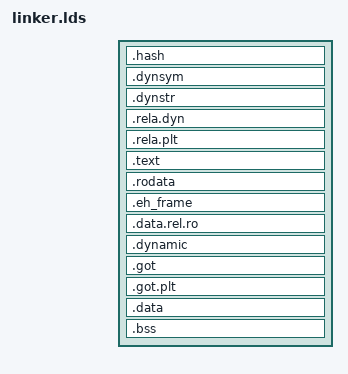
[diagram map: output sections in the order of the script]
/*******************************************************************************
* Copyright (c) 2015 Intel Corporation
*
* Licensed under the Apache License, Version 2.0 (the "License");
* you may not use this file except in compliance with the License.
* You may obtain a copy of the License at
*
*      http://www.apache.org/licenses/LICENSE-2.0
*
* Unless required by applicable law or agreed to in writing, software
* distributed under the License is distributed on an "AS IS" BASIS,
* WITHOUT WARRANTIES OR CONDITIONS OF ANY KIND, either express or implied.
* See the License for the specific language governing permissions and
* limitations under the License.
*******************************************************************************/

OUTPUT_FORMAT("elf64-x86-64", "elf64-x86-64",
	      "elf64-x86-64")
OUTPUT_ARCH(i386:x86-64)

ENTRY(mon_main_asm);

SECTIONS
{
  /* Read-only sections, merged into text segment: */
  . = SEGMENT_START("text-segment", 0) + SIZEOF_HEADERS;
  .hash           : { *(.hash) }
  .dynsym         : { *(.dynsym) }
  .dynstr         : { *(.dynstr) }
  .rela.dyn       :
    {
      *(.rela.init)
      *(.rela.text .rela.text.* .rela.gnu.linkonce.t.*)
      *(.rela.fini)
      *(.rela.rodata .rela.rodata.* .rela.gnu.linkonce.r.*)
      *(.rela.data .rela.data.* .rela.gnu.linkonce.d.*)
      *(.rela.tdata .rela.tdata.* .rela.gnu.linkonce.td.*)
      *(.rela.tbss .rela.tbss.* .rela.gnu.linkonce.tb.*)
      *(.rela.ctors)
      *(.rela.dtors)
      *(.rela.got)
      *(.rela.bss .rela.bss.* .rela.gnu.linkonce.b.*)
      *(.rela.ldata .rela.ldata.* .rela.gnu.linkonce.l.*)
      *(.rela.lbss .rela.lbss.* .rela.gnu.linkonce.lb.*)
      *(.rela.lrodata .rela.lrodata.* .rela.gnu.linkonce.lr.*)
      *(.rela.ifunc)
    }
  .rela.plt       :
    {
      *(.rela.plt)
      *(.rela.iplt)
    }
  .text           :
  {
    *(.text.unlikely .text.*_unlikely)
    *(.text.exit .text.exit.*)
    *(.text.startup .text.startup.*)
    *(.text.hot .text.hot.*)
    *(.text .stub .text.* .gnu.linkonce.t.*)
    /* .gnu.warning sections are handled specially by elf32.em.  */
    *(.gnu.warning)
  } =0x90909090
  .rodata         : { *(.rodata .rodata.* .gnu.linkonce.r.*) }
  .eh_frame       : { *(.eh_frame) }
  /* Adjust the address for the data segment.  We want to adjust up to
     the same address within the page on the next page up.  */
  . = ALIGN (4k);
  .data.rel.ro : { *(.data.rel.ro.local* .gnu.linkonce.d.rel.ro.local.*) *(.data.rel.ro* .gnu.linkonce.d.rel.ro.*) }
  .dynamic        : { *(.dynamic) }
  .got            : { *(.got) *(.igot) }
  .got.plt        : { *(.got.plt)  *(.igot.plt) }
  .data           :
  {
    *(.data .data.* .gnu.linkonce.d.*)
  }
  .bss            :
  {
   *(.dynbss)
   *(.bss .bss.* .gnu.linkonce.b.*)
   *(COMMON)
   /* Align here to ensure that the .bss section occupies space up to
      _end.  Align after .bss to ensure correct alignment even if the
      .bss section disappears because there are no input sections.
      FIXME: Why do we need it? When there is no .bss section, we don't
      pad the .data section.  */
   . = ALIGN(. != 0 ? 64 / 8 : 1);
  }
}
